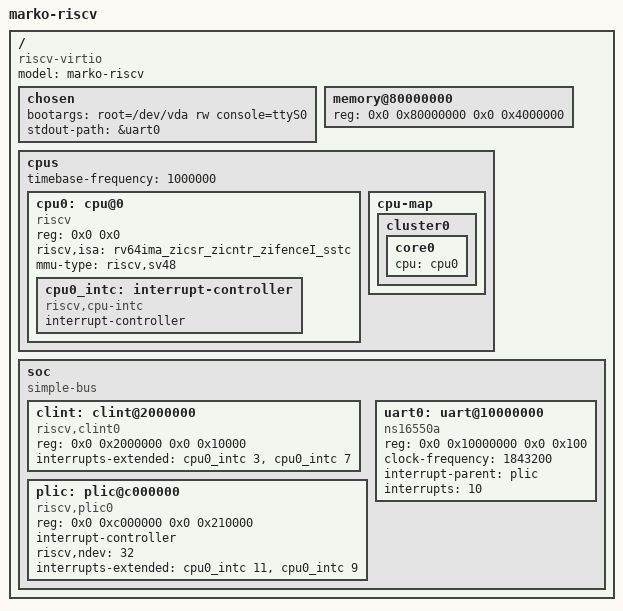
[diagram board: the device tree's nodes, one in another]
/dts-v1/;

/ {
    model = "marko-riscv";
    compatible = "riscv-virtio";
    #address-cells = <2>;
    #size-cells = <2>;

    /* ----------------------------------------------------------------
     *  Boot Configuration
     * ---------------------------------------------------------------- */
    chosen {
        bootargs = "root=/dev/vda rw console=ttyS0";
        stdout-path = &uart0;
    };

    /* ----------------------------------------------------------------
     *  System Memory — 64 MiB @ 0x8000_0000
     * ---------------------------------------------------------------- */
    memory@80000000 {
        device_type = "memory";
        reg = <0x0 0x80000000 0x0 0x4000000>;
    };

    /* ----------------------------------------------------------------
     *  CPUs
     * ---------------------------------------------------------------- */
    cpus {
        #address-cells = <2>;
        #size-cells = <0>;
        timebase-frequency = <1000000>; /* 1 MHz */

        cpu0: cpu@0 {
            device_type = "cpu";
            reg = <0x0 0x0>;
            status = "okay";
            compatible = "riscv";
            riscv,isa = "rv64ima_zicsr_zicntr_zifenceI_sstc";
            mmu-type = "riscv,sv48";

            cpu0_intc: interrupt-controller {
                #interrupt-cells = <1>;
                compatible = "riscv,cpu-intc";
                interrupt-controller;
            };
        };

        cpu-map {
            cluster0 {
                core0 {
                    cpu = <&cpu0>;
                };
            };
        };
    };

    /* ----------------------------------------------------------------
     *  SoC Peripherals
     * ---------------------------------------------------------------- */
    soc {
        #address-cells = <2>;
        #size-cells = <2>;
        compatible = "simple-bus";
        ranges;

        /* ---------- CLINT — Core Local Interrupter ---------- */
        clint: clint@2000000 {
            compatible = "riscv,clint0";
            reg = <0x0 0x2000000 0x0 0x10000>;
            interrupts-extended = <
                &cpu0_intc 3    /* M-mode software interrupt */
                &cpu0_intc 7    /* M-mode timer interrupt    */
            >;
        };

        /* ---------- PLIC — Platform-Level Interrupt Controller ---------- */
        plic: plic@c000000 {
            #interrupt-cells = <1>;
            #address-cells = <0>;
            compatible = "riscv,plic0";
            reg = <0x0 0xc000000 0x0 0x210000>;
            interrupt-controller;
            riscv,ndev = <32>;
            interrupts-extended = <
                &cpu0_intc 11   /* M-mode external interrupt */
                &cpu0_intc 9    /* S-mode external interrupt */
            >;
        };

        /* ---------- UART0 — NS16550A Serial Controller ---------- */
        uart0: uart@10000000 {
            compatible = "ns16550a";
            reg = <0x0 0x10000000 0x0 0x100>;
            clock-frequency = <1843200>;
            interrupt-parent = <&plic>;
            interrupts = <10>;
            status = "okay";
        };
    };
};
